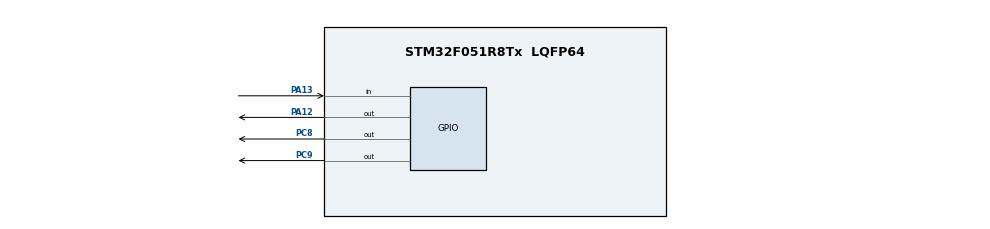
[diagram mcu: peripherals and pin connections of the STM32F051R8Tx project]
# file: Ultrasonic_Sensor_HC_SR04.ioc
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Mcu.Family=STM32F0
Mcu.Name=STM32F051R8Tx
Mcu.Package=LQFP64
PA12.Signal=GPIO_Output
PA13.Signal=GPIO_Input
PC8.Signal=GPIO_Output
PC9.Signal=GPIO_Output
ProjectManager.HeapSize=0x200
ProjectManager.StackSize=0x400
ProjectManager.TargetToolchain=TrueSTUDIO
board=custom

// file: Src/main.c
/* USER CODE BEGIN Header */
/**
  ******************************************************************************
  * @file           : main.c
  * @brief          : Main program body
  ******************************************************************************
  ** This notice applies to any and all portions of this file
  * that are not between comment pairs USER CODE BEGIN and
  * USER CODE END. Other portions of this file, whether
  * inserted by the user or by software development tools
  * are owned by their respective copyright owners.
  *
  * COPYRIGHT(c) 2019 STMicroelectronics
  *
  * Redistribution and use in source and binary forms, with or without modification,
  * are permitted provided that the following conditions are met:
  *   1. Redistributions of source code must retain the above copyright notice,
  *      this list of conditions and the following disclaimer.
  *   2. Redistributions in binary form must reproduce the above copyright notice,
  *      this list of conditions and the following disclaimer in the documentation
  *      and/or other materials provided with the distribution.
  *   3. Neither the name of STMicroelectronics nor the names of its contributors
  *      may be used to endorse or promote products derived from this software
  *      without specific prior written permission.
  *
  * THIS SOFTWARE IS PROVIDED BY THE COPYRIGHT HOLDERS AND CONTRIBUTORS "AS IS"
  * AND ANY EXPRESS OR IMPLIED WARRANTIES, INCLUDING, BUT NOT LIMITED TO, THE
  * IMPLIED WARRANTIES OF MERCHANTABILITY AND FITNESS FOR A PARTICULAR PURPOSE ARE
  * DISCLAIMED. IN NO EVENT SHALL THE COPYRIGHT HOLDER OR CONTRIBUTORS BE LIABLE
  * FOR ANY DIRECT, INDIRECT, INCIDENTAL, SPECIAL, EXEMPLARY, OR CONSEQUENTIAL
  * DAMAGES (INCLUDING, BUT NOT LIMITED TO, PROCUREMENT OF SUBSTITUTE GOODS OR
  * SERVICES; LOSS OF USE, DATA, OR PROFITS; OR BUSINESS INTERRUPTION) HOWEVER
  * CAUSED AND ON ANY THEORY OF LIABILITY, WHETHER IN CONTRACT, STRICT LIABILITY,
  * OR TORT (INCLUDING NEGLIGENCE OR OTHERWISE) ARISING IN ANY WAY OUT OF THE USE
  * OF THIS SOFTWARE, EVEN IF ADVISED OF THE POSSIBILITY OF SUCH DAMAGE.
  *
  ******************************************************************************
  */
/* USER CODE END Header */

#include "main.h"
#include "delay.h"

/* USER CODE BEGIN Includes */
//The value to save distance of sensor's measure.
	float temp;
//End add.

/* USER CODE END Includes */

void SystemClock_Config(void);
static void MX_GPIO_Init(void);

int main(void)
{

  /* MCU Configuration--------------------------------------------------------*/

  /* Reset of all peripherals, Initializes the Flash interface and the Systick. */
	SysTick_Init();
	HAL_Init();

  /* Configure the system clock */
  SystemClock_Config();

  /* Initialize all configured peripherals */
  MX_GPIO_Init();

  /* Infinite loop */
  while (1)
  {
	  ultras(&temp);
	  printf("HTV show value temp =%f",temp);
  }
}

void SystemClock_Config(void)
{
  RCC_OscInitTypeDef RCC_OscInitStruct = {0};
  RCC_ClkInitTypeDef RCC_ClkInitStruct = {0};

  /**Initializes the CPU, AHB and APB busses clocks
  */
  RCC_OscInitStruct.OscillatorType = RCC_OSCILLATORTYPE_HSI;
  RCC_OscInitStruct.HSIState = RCC_HSI_ON;
  RCC_OscInitStruct.HSICalibrationValue = RCC_HSICALIBRATION_DEFAULT;
  RCC_OscInitStruct.PLL.PLLState = RCC_PLL_NONE;
  if (HAL_RCC_OscConfig(&RCC_OscInitStruct) != HAL_OK)
  {
    Error_Handler();
  }
  /**Initializes the CPU, AHB and APB busses clocks
  */
  RCC_ClkInitStruct.ClockType = RCC_CLOCKTYPE_HCLK|RCC_CLOCKTYPE_SYSCLK
                              |RCC_CLOCKTYPE_PCLK1;
  RCC_ClkInitStruct.SYSCLKSource = RCC_SYSCLKSOURCE_HSI;
  RCC_ClkInitStruct.AHBCLKDivider = RCC_SYSCLK_DIV1;
  RCC_ClkInitStruct.APB1CLKDivider = RCC_HCLK_DIV1;

  if (HAL_RCC_ClockConfig(&RCC_ClkInitStruct, FLASH_LATENCY_0) != HAL_OK)
  {
    Error_Handler();
  }
}

static void MX_GPIO_Init(void)
{
  GPIO_InitTypeDef GPIO_InitStruct = {0};

  /* GPIO Ports Clock Enable */
  __HAL_RCC_GPIOC_CLK_ENABLE();
  __HAL_RCC_GPIOA_CLK_ENABLE();

  /*Configure GPIO pin Output Level */
  HAL_GPIO_WritePin(GPIOC, GPIO_PIN_8|GPIO_PIN_9, GPIO_PIN_RESET);

  /*Configure GPIO pin Output Level */
  HAL_GPIO_WritePin(GPIOA, GPIO_PIN_12, GPIO_PIN_RESET);

  /*Configure GPIO pins : PC8 PC9 */
  GPIO_InitStruct.Pin = GPIO_PIN_8|GPIO_PIN_9;
  GPIO_InitStruct.Mode = GPIO_MODE_OUTPUT_PP;
  GPIO_InitStruct.Pull = GPIO_NOPULL;
  GPIO_InitStruct.Speed = GPIO_SPEED_FREQ_LOW;
  HAL_GPIO_Init(GPIOC, &GPIO_InitStruct);

  /*Configure GPIO pin : PA12 */
  GPIO_InitStruct.Pin = GPIO_PIN_12;
  GPIO_InitStruct.Mode = GPIO_MODE_OUTPUT_PP;
  GPIO_InitStruct.Pull = GPIO_NOPULL;
  GPIO_InitStruct.Speed = GPIO_SPEED_FREQ_LOW;
  HAL_GPIO_Init(GPIOA, &GPIO_InitStruct);

  /*Configure GPIO pin : PA13 */
  GPIO_InitStruct.Pin = GPIO_PIN_13;
  GPIO_InitStruct.Mode = GPIO_MODE_INPUT;
  GPIO_InitStruct.Pull = GPIO_NOPULL;
  HAL_GPIO_Init(GPIOA, &GPIO_InitStruct);
}
/*Ham xu ly tin hieu tu ultrasonic
 * para : *p, pointer to save value of distance
 *
 * */

float ultras(float *p)
{
	uint8_t i;
	uint8_t j;
	float Ultr_Temp = 0;
	for(i = 0; i<5; i++)
	{
		HAL_GPIO_WritePin(GPIOA,GPIO_PIN_12,0);
		HAL_GPIO_WritePin(GPIOA,GPIO_PIN_12,1);
		HAL_GPIO_WritePin(GPIOA,GPIO_PIN_12,0);
		while(HAL_GPIO_ReadPin(GPIOA,GPIO_PIN_13) == 0 );
		while(HAL_GPIO_ReadPin(GPIOA,GPIO_PIN_13) == 1 )
		{
			j++;
		}
		 Ultr_Temp+=340/2*j*10;// max = 3m, haha, somtimes can reach 5-6m which is funny
		 j=0;
		 HAL_Delay(60);
	}
	return j;

}

/* USER CODE END 4 */

void Error_Handler(void)
{
}

/************************ (C) COPYRIGHT STMicroelectronics *****END OF FILE****/
